VERSION ""

NS_ :

BS_:

BU_:

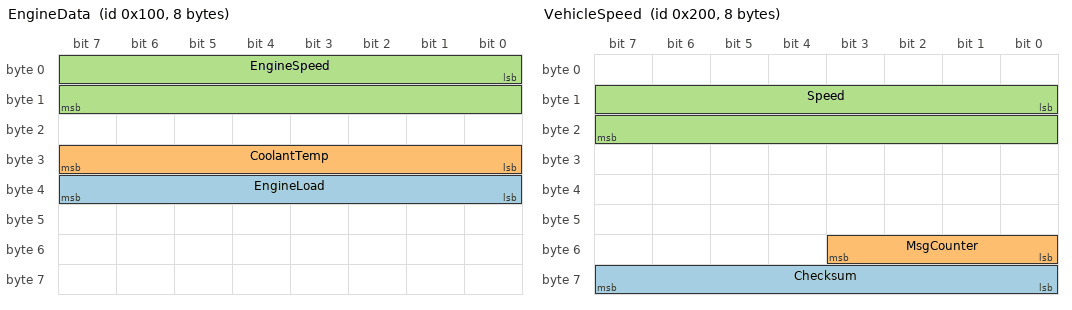
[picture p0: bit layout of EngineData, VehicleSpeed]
BO_ 256 EngineData: 8 ECU_Engine
 SG_ EngineLoad : 32|8@1+ (0.5,0) [0|100] "%" Vector__XXX
 SG_ CoolantTemp : 24|8@1+ (1,-40) [-40|215] "C" Vector__XXX
 SG_ EngineSpeed : 0|16@1+ (0.5,0) [0|8000] "rpm" Vector__XXX

BO_ 512 VehicleSpeed: 8 ECU_Chassis
 SG_ Checksum : 56|8@1+ (1,0) [0|255] "" Vector__XXX
 SG_ MsgCounter : 48|4@1+ (1,0) [0|15] "" Vector__XXX
 SG_ Speed : 8|16@1+ (0.01,0) [0|300] "km/h" Vector__XXX

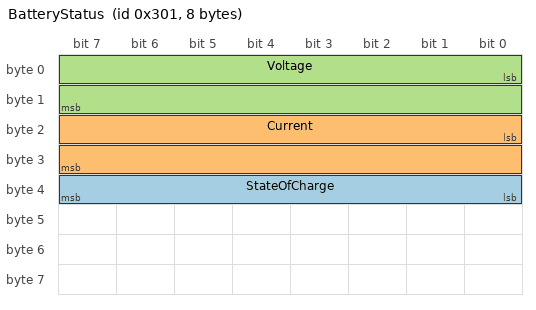
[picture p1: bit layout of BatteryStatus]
BO_ 769 BatteryStatus: 8 ECU_Battery
 SG_ StateOfCharge : 32|8@1+ (0.5,0) [0|100] "%" Vector__XXX
 SG_ Current : 16|16@1- (0.1,0) [-300|300] "A" Vector__XXX
 SG_ Voltage : 0|16@1+ (0.1,0) [0|500] "V" Vector__XXX

BO_ 1280 Diagnostics: 8 ECU_Engine
 SG_ FaultCount : 0|8@1+ (1,0) [0|255] "" Vector__XXX

BA_DEF_ BO_  "GenMsgCycleTime" INT 0 65535;
BA_DEF_DEF_  "GenMsgCycleTime" 0;
BA_ "GenMsgCycleTime" BO_ 256 10;
BA_ "GenMsgCycleTime" BO_ 512 20;
BA_ "GenMsgCycleTime" BO_ 769 100;
BA_ "GenMsgCycleTime" BO_ 1280 1000;
